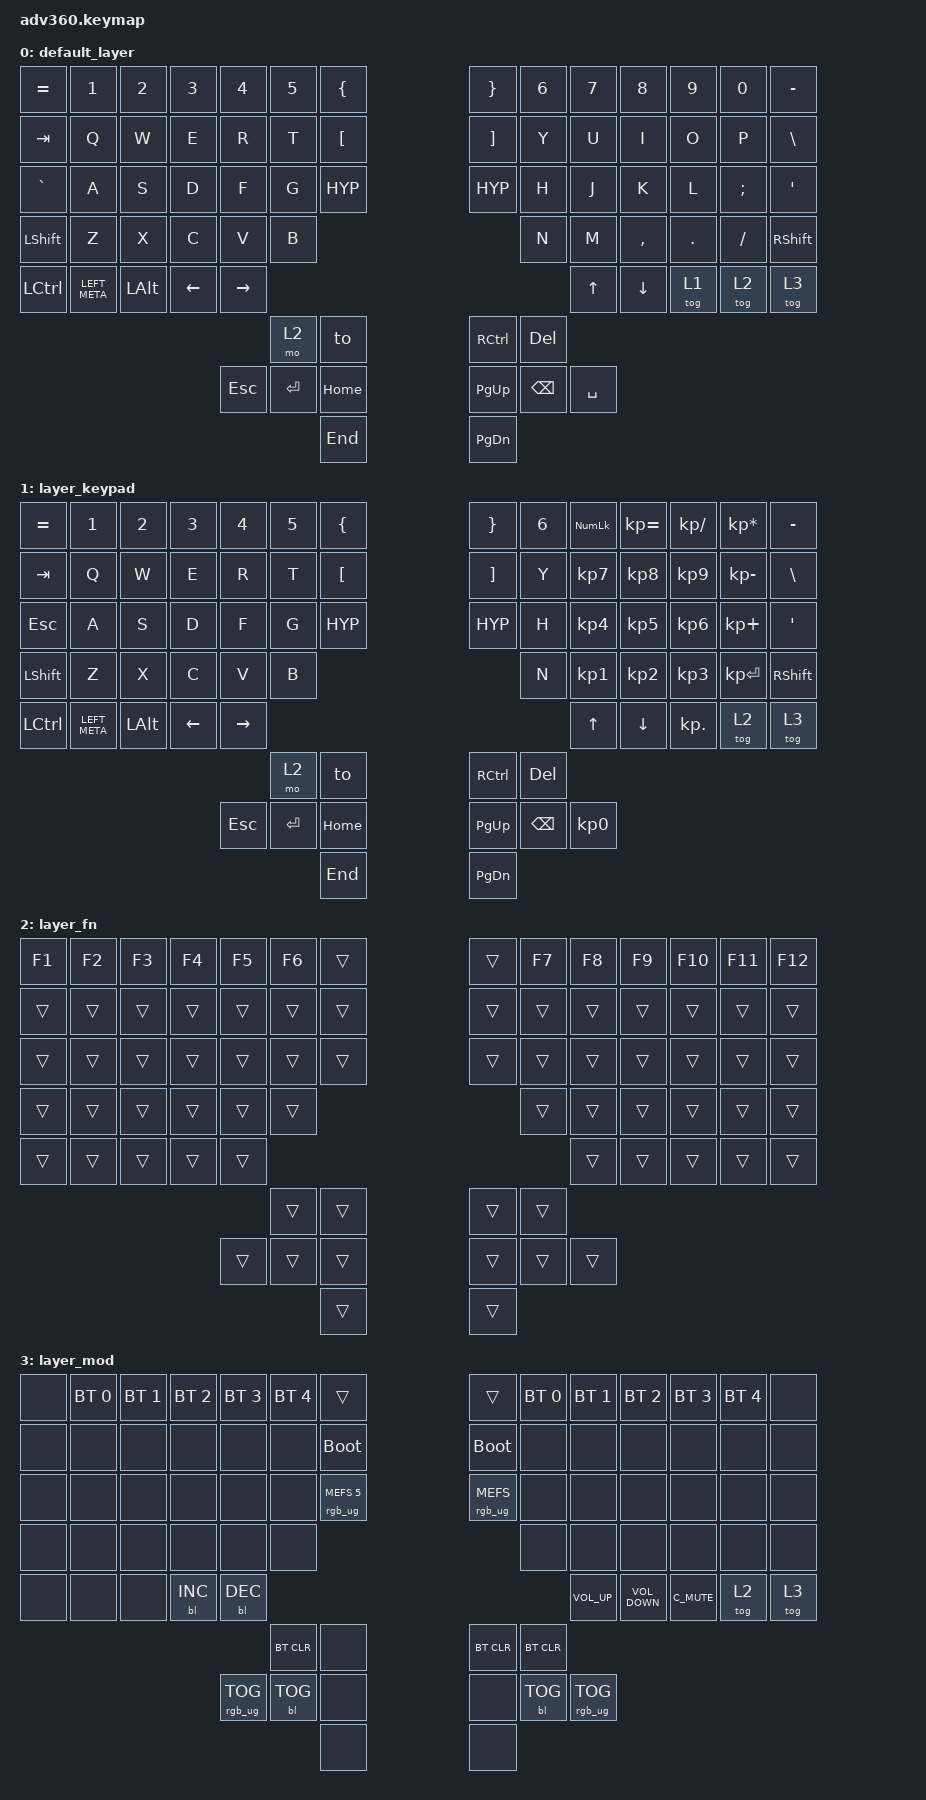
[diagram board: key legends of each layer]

/*
 * Copyright (c) 2020 The ZMK Contributors
 *
 * SPDX-License-Identifier: MIT
 */


/* THIS FILE WAS GENERATED!
 *
 * This file was generated automatically. You may or may not want to
 * edit it directly.
 */

#include <behaviors.dtsi>
#include <dt-bindings/zmk/keys.h>
#include <dt-bindings/zmk/bt.h>
#include <dt-bindings/zmk/rgb.h>
#include <dt-bindings/zmk/backlight.h>

#define ___ &trans
#define HYP LS(LC(LA(LGUI)))

/ {
  behaviors {
    #include "macros.dtsi"

    hm: homerow_mods {
        compatible = "zmk,behavior-hold-tap";
        label = "HOMEROW_MODS";
        #binding-cells = <2>;
        tapping-term-ms = <200>;
        quick_tap_ms = <175>;
        flavor = "tap-preferred";
        bindings = <&kp>, <&kp>
    };
  };

    chosen {
          zmk,matrix_transform = &urobs_transform;
    };

    keymap {
        compatible = "zmk,keymap";


        default_layer {
            bindings = <
&kp EQUAL         &kp N1         &kp N2         &kp N3     &kp N4      &kp N5         &kp LEFT_BRACE                                         &kp RIGHT_BRACE     &kp N6      &kp N7     &kp N8      &kp N9     &kp N0    &kp MINUS
&kp TAB           &kp Q          &kp W          &kp E      &kp R       &kp T          &kp LEFT_BRACKET                                       &kp RIGHT_BRACKET   &kp Y       &kp U      &kp I       &kp O      &kp P     &kp BSLH
&kp GRAVE         &kp A          &kp S          &kp D      &kp F       &kp G          &kp HYP                                                &kp HYP             &kp H       &kp J      &kp K       &kp L      &kp SEMI  &kp SQT
&kp LSHFT         &kp Z          &kp X          &kp C      &kp V       &kp B                                                                                     &kp N       &kp M      &kp COMMA   &kp DOT    &kp FSLH  &kp RSHFT
&kp LEFT_CONTROL  &kp LEFT_META  &kp LEFT_ALT   &kp LEFT   &kp RIGHT                                                                                                         &kp UP     &kp DOWN    &tog 1     &tog 2    &tog 3
                                                                        &mo 2         @to 0                                                 &kp RCTRL   &kp DEL
                                                            &kp ESCAPE  &kp RETURN    &kp HOME                                              &kp PG_UP   &kp BACKSPACE  &kp SPACE 
                                                                                      &kp END                                               &kp PG_DN
            >;
        };

        layer_keypad {
            bindings = <
&kp EQUAL           &kp N1         &kp N2         &kp N3     &kp N4      &kp N5         &kp LEFT_BRACE                                        &kp RIGHT_BRACE     &kp N6  &kp KP_NUM  &kp KP_EQUAL    &kp KP_DIVIDE   &kp KP_MULTIPLY     &kp MINUS
&kp TAB             &kp Q          &kp W          &kp E      &kp R       &kp T          &kp LEFT_BRACKET                                      &kp RIGHT_BRACKET   &kp Y   &kp KP_N7   &kp KP_N8       &kp KP_N9       &kp KP_MINUS        &kp BSLH
&kp ESC             &kp A          &kp S          &kp D      &kp F       &kp G          &kp HYP                                               &kp HYP             &kp H   &kp KP_N4   &kp KP_N5       &kp KP_N6       &kp KP_PLUS         &kp SQT
&kp LSHFT           &kp Z          &kp X          &kp C      &kp V       &kp B                                                                                    &kp N   &kp KP_N1   &kp KP_N2       &kp KP_N3       &kp KP_ENTER        &kp RSHFT
&kp LEFT_CONTROL    &kp LEFT_META  &kp LEFT_ALT   &kp LEFT   &kp RIGHT                                                                                                    &kp UP      &kp DOWN        &kp KP_DOT      &tog 2              &tog 3
                                                                         &mo 2          @to 0                                                 &kp RCTRL   &kp DEL
                                                            &kp ESCAPE   &kp RETURN     &kp HOME                                              &kp PG_UP   &kp BACKSPACE  &kp KP_N0 
                                                                                        &kp END                                               &kp PG_DN
            >;
        };

        layer_fn {
            bindings = <
&kp F1  &kp F2  &kp F3  &kp F4  &kp F5  &kp F6  &trans        &trans  &kp F7  &kp F8  &kp F9  &kp F10  &kp F11  &kp F12
&trans  &trans  &trans  &trans  &trans  &trans  &trans        &trans  &trans  &trans  &trans  &trans   &trans   &trans
&trans  &trans  &trans  &trans  &trans  &trans  &trans        &trans  &trans  &trans  &trans  &trans   &trans   &trans   
&trans  &trans  &trans  &trans  &trans  &trans                        &trans  &trans  &trans  &trans   &trans   &trans
&trans  &trans  &trans  &trans  &trans                                        &trans  &trans  &trans   &trans   &trans
                                        &trans  &trans        &trans  &trans
                                &trans  &trans  &trans        &trans  &trans  &trans
                                                &trans        &trans
            >;
        };

        layer_mod {
            bindings = <
&none  &bt BT_SEL 0  &bt BT_SEL 1  &bt BT_SEL 2  &bt BT_SEL 3    &bt BT_SEL 4      &trans                               &trans                   &bt BT_SEL 0  &bt BT_SEL 1     &bt BT_SEL 2       &bt BT_SEL 3     &bt BT_SEL 4      &none
&none  &none         &none         &none         &none           &none             &bootloader                          &bootloader              &none         &none            &none              &none            &none             &none
&none  &none         &none         &none         &none           &none             &rgb_ug RGB_MEFS_CMD 5               &rgb_ug RGB_MEFS_CMD     &none         &none            &none              &none            &none             &none
&none  &none         &none         &none         &none           &none                                                                           &none         &none            &none              &none            &none             &none 
&none  &none         &none         &bl BL_INC    &bl BL_DEC                                                                                                    &kp C_VOLUME_UP  &kp C_VOLUME_DOWN  C_MUTE           &tog 2            &tog 3 
                                                                 &bt BT_CLR        &none                           &bt BT_CLR      &bt BT_CLR
                                                 &rgb_ug RGB_TOG &bl BL_TOG        &none                           &none           &bl BL_TOG     &rgb_ug RGB_TOG
                                                                                   &none                           &none
            >;
        };

    };
};
